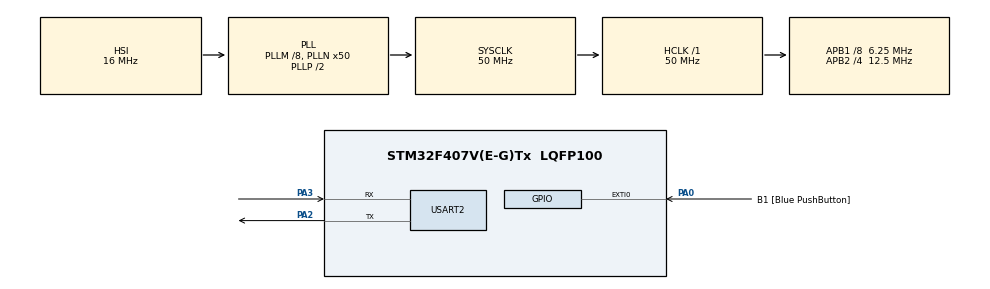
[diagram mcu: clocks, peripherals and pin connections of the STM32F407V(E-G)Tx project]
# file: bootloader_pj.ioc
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Mcu.Family=STM32F4
Mcu.Name=STM32F407V(E-G)Tx
Mcu.Package=LQFP100
NVIC.PriorityGroup=NVIC_PRIORITYGROUP_0
PA0-WKUP.GPIO_Label=B1 [Blue PushButton]
PA0-WKUP.GPIO_ModeDefaultEXTI=GPIO_MODE_EVT_RISING
PA0-WKUP.GPIO_PuPd=GPIO_NOPULL
PA0-WKUP.Signal=GPXTI0
PA13.GPIO_Label=SWDIO
PA13.Signal=SYS_JTMS-SWDIO
PA2.Mode=Asynchronous
PA2.Signal=USART2_TX
PA3.Mode=Asynchronous
PA3.Signal=USART2_RX
ProjectManager.HeapSize=0x200
ProjectManager.StackSize=0x400
ProjectManager.TargetToolchain=STM32CubeIDE
RCC.48MHZClocksFreq_Value=14285714.285714285
RCC.AHBFreq_Value=50000000
RCC.APB1CLKDivider=RCC_HCLK_DIV8
RCC.APB1Freq_Value=6250000
RCC.APB1TimFreq_Value=12500000
RCC.APB2CLKDivider=RCC_HCLK_DIV4
RCC.APB2Freq_Value=12500000
RCC.APB2TimFreq_Value=25000000
RCC.CortexFreq_Value=50000000
RCC.HCLKFreq_Value=50000000
RCC.HSE_VALUE=8000000
RCC.HSI_VALUE=16000000
RCC.LSE_VALUE=32768
RCC.PLLM=8
RCC.PLLN=50
RCC.PLLQ=7
RCC.SYSCLKFreq_VALUE=50000000
RCC.SYSCLKSource=RCC_SYSCLKSOURCE_PLLCLK
RCC.VCOOutputFreq_Value=100000000
USART2.VirtualMode=VM_ASYNC
VP_CRC_VS_CRC.Mode=CRC_Activate
board=STM32F407G-DISC1

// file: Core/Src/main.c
/* USER CODE BEGIN Header */
/**
  ******************************************************************************
  * @file           : main.c
  * @brief          : Main program body
  ******************************************************************************
  * @attention
  *
  * Copyright (c) 2026 STMicroelectronics.
  * All rights reserved.
  *
  * This software is licensed under terms that can be found in the LICENSE file
  * in the root directory of this software component.
  * If no LICENSE file comes with this software, it is provided AS-IS.
  *
  ******************************************************************************
  */
/* USER CODE END Header */
#include "main.h"

/* USER CODE BEGIN Includes */
#include <stdarg.h>
#include <string.h>
#include <stdio.h>
#include "boot_config.h"
/* USER CODE END Includes */

/* USER CODE BEGIN PM */
#define BL_RX_LEN					200U
/* USER CODE END PM */

CRC_HandleTypeDef hcrc;

UART_HandleTypeDef huart2;

/* USER CODE BEGIN PV */
uint8_t bl_rx_buffer[BL_RX_LEN];
uint8_t supported_commands[] = {
                                 BL_GET_VER ,
                                 BL_GET_HELP,
                                 BL_GET_CID,
                                 BL_GET_RDP_STATUS,
                                 BL_GO_TO_ADDR,
                                 BL_FLASH_ERASE,
                                 BL_MEM_WRITE,
                                 BL_READ_SECTOR_P_STATUS} ;

/* USER CODE END PV */

void SystemClock_Config(void);
static void MX_GPIO_Init(void);
static void MX_CRC_Init(void);
static void MX_USART2_UART_Init(void);
/* USER CODE BEGIN PFP */
static void printmsg(char *format,...);
void  bootloader_uart_read_data(void);
void  bootloader_jump_to_user_app(void);
/* USER CODE END PFP */

int main(void)
{

  /* MCU Configuration--------------------------------------------------------*/

  /* Reset of all peripherals, Initializes the Flash interface and the Systick. */
  HAL_Init();

  /* Configure the system clock */
  SystemClock_Config();

  /* Initialize all configured peripherals */
  MX_GPIO_Init();
  MX_CRC_Init();
  MX_USART2_UART_Init();
  /* USER CODE BEGIN 2 */
  /* Lets check whether button is pressed or not, if not pressed jump to user application */
	if (HAL_GPIO_ReadPin(B1_GPIO_Port, B1_Pin)) {

		/* Bootloader mode */
		///printmsg("BL_DEBUG_MSG:Bootloader mode\n");
		bootloader_uart_read_data();
	} else {

		/* User application mode */
		//printmsg("BL_DEBUG_MSG:User application mode\n");
		bootloader_jump_to_user_app();

	}
  /* USER CODE END 2 */

  /* Infinite loop */
  while (1)
  {

  }
}

void SystemClock_Config(void)
{
  RCC_OscInitTypeDef RCC_OscInitStruct = {0};
  RCC_ClkInitTypeDef RCC_ClkInitStruct = {0};

  /** Configure the main internal regulator output voltage
  */
  __HAL_RCC_PWR_CLK_ENABLE();
  __HAL_PWR_VOLTAGESCALING_CONFIG(PWR_REGULATOR_VOLTAGE_SCALE1);

  /** Initializes the RCC Oscillators according to the specified parameters
  * in the RCC_OscInitTypeDef structure.
  */
  RCC_OscInitStruct.OscillatorType = RCC_OSCILLATORTYPE_HSI;
  RCC_OscInitStruct.HSIState = RCC_HSI_ON;
  RCC_OscInitStruct.HSICalibrationValue = RCC_HSICALIBRATION_DEFAULT;
  RCC_OscInitStruct.PLL.PLLState = RCC_PLL_ON;
  RCC_OscInitStruct.PLL.PLLSource = RCC_PLLSOURCE_HSI;
  RCC_OscInitStruct.PLL.PLLM = 8;
  RCC_OscInitStruct.PLL.PLLN = 50;
  RCC_OscInitStruct.PLL.PLLP = RCC_PLLP_DIV2;
  RCC_OscInitStruct.PLL.PLLQ = 7;
  if (HAL_RCC_OscConfig(&RCC_OscInitStruct) != HAL_OK)
  {
    Error_Handler();
  }

  /** Initializes the CPU, AHB and APB buses clocks
  */
  RCC_ClkInitStruct.ClockType = RCC_CLOCKTYPE_HCLK|RCC_CLOCKTYPE_SYSCLK
                              |RCC_CLOCKTYPE_PCLK1|RCC_CLOCKTYPE_PCLK2;
  RCC_ClkInitStruct.SYSCLKSource = RCC_SYSCLKSOURCE_PLLCLK;
  RCC_ClkInitStruct.AHBCLKDivider = RCC_SYSCLK_DIV1;
  RCC_ClkInitStruct.APB1CLKDivider = RCC_HCLK_DIV8;
  RCC_ClkInitStruct.APB2CLKDivider = RCC_HCLK_DIV4;

  if (HAL_RCC_ClockConfig(&RCC_ClkInitStruct, FLASH_LATENCY_1) != HAL_OK)
  {
    Error_Handler();
  }
}

static void MX_CRC_Init(void)
{

  hcrc.Instance = CRC;
  if (HAL_CRC_Init(&hcrc) != HAL_OK)
  {
    Error_Handler();
  }

}

static void MX_USART2_UART_Init(void)
{

  huart2.Instance = USART2;
  huart2.Init.BaudRate = 115200;
  huart2.Init.WordLength = UART_WORDLENGTH_8B;
  huart2.Init.StopBits = UART_STOPBITS_1;
  huart2.Init.Parity = UART_PARITY_NONE;
  huart2.Init.Mode = UART_MODE_TX_RX;
  huart2.Init.HwFlowCtl = UART_HWCONTROL_NONE;
  huart2.Init.OverSampling = UART_OVERSAMPLING_16;
  if (HAL_UART_Init(&huart2) != HAL_OK)
  {
    Error_Handler();
  }

}

static void MX_GPIO_Init(void)
{
  GPIO_InitTypeDef GPIO_InitStruct = {0};

  /* GPIO Ports Clock Enable */
  __HAL_RCC_GPIOA_CLK_ENABLE();

  /*Configure GPIO pin : B1_Pin */
  GPIO_InitStruct.Pin = B1_Pin;
  GPIO_InitStruct.Mode = GPIO_MODE_EVT_RISING;
  GPIO_InitStruct.Pull = GPIO_NOPULL;
  HAL_GPIO_Init(B1_GPIO_Port, &GPIO_InitStruct);

}

/* USER CODE BEGIN 4 */
static void printmsg(char *format,...) {
  char str[80];

  /*Extract the the argument list using VA apis */
  va_list args;
  va_start(args, format);
  vsprintf(str, format,args);
  HAL_UART_Transmit(&huart2,(uint8_t *)str, strlen(str),HAL_MAX_DELAY);
  va_end(args);
}

void bootloader_uart_read_data(void) {
  uint8_t rcv_len=0;

  while(1) {
    memset(bl_rx_buffer,0,200);
    /* we will read and decode the commands coming from host */
    /* first read only one byte from the host , which is the "length" field of the command packet */
    HAL_UART_Receive(&huart2, bl_rx_buffer, 1, HAL_MAX_DELAY);
    rcv_len= bl_rx_buffer[0];
    HAL_UART_Receive(&huart2, &bl_rx_buffer[1], rcv_len, HAL_MAX_DELAY);

    switch ( bl_rx_buffer[1] ) {
      case BL_GET_VER:
          bootloader_handle_getver_cmd(bl_rx_buffer);
          break;
      case BL_GET_HELP:
          bootloader_handle_gethelp_cmd(bl_rx_buffer);
          break;
      case BL_GET_CID:
          bootloader_handle_getcid_cmd(bl_rx_buffer);
          break;
      case BL_GET_RDP_STATUS:
          bootloader_handle_getrdp_cmd(bl_rx_buffer);
          break;
      case BL_GO_TO_ADDR:
          bootloader_handle_go_cmd(bl_rx_buffer);
          break;
      case BL_FLASH_ERASE:
          bootloader_handle_flash_erase_cmd(bl_rx_buffer);
          break;
      case BL_MEM_WRITE:
          bootloader_handle_mem_write_cmd(bl_rx_buffer);
          break;
      case BL_EN_RW_PROTECT:
          bootloader_handle_en_rw_protect(bl_rx_buffer);
          break;
      case BL_MEM_READ:
          bootloader_handle_mem_read(bl_rx_buffer);
          break;
      case BL_READ_SECTOR_P_STATUS:
          bootloader_handle_read_sector_protection_status(bl_rx_buffer);
          break;
      case BL_OTP_READ:
          bootloader_handle_read_otp(bl_rx_buffer);
          break;
      case BL_DIS_R_W_PROTECT:
          bootloader_handle_dis_rw_protect(bl_rx_buffer);
          break;
       default:
         // printmsg("BL_DEBUG_MSG:Invalid command code received from host \n");
          break;

    }
  }
}
void  bootloader_jump_to_user_app(void)
{
	/* Function pointer to hold the address of the reset handler of the user app */
	void (*app_reset_handler)(void);

	/* Configure the MSP by reading the value from the app vector table (slot A + header) */
	uint32_t msp_value = *(volatile uint32_t *)BOOT_APP_VECTOR_ADDR;
	printmsg("BL_DEBUG_MSG:MSP value : %#x\n",msp_value);

	/* Set MSP */
	__set_MSP(msp_value);

	/* Fetch the reset handler address from the user application  from the location BOOT_APP_VECTOR_ADDR */
	uint32_t reset_handler_address = *(volatile uint32_t *) (BOOT_APP_VECTOR_ADDR + 4);

	app_reset_handler = (void *)reset_handler_address;

	printmsg("BL_DEBUG_MSG: app reset handler addr : %#x\n",app_reset_handler);

	/* Jump to reset handler of the user application */
	app_reset_handler();
}

/* USER CODE END 4 */

void Error_Handler(void)
{
  __disable_irq();
  while (1)
  {
  }
}
